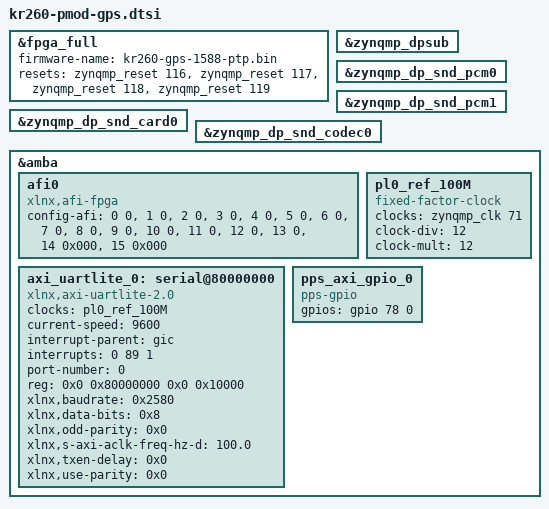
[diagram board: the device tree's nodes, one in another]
// SPDX-License-Identifier: Apache-2.0
/*
 * dts file for Xilinx Kr260 GPS-1588-PTP
 *
 * (C) Copyright 2020 - 2021, Xilinx, Inc.
 * Copyright (C) 2022 - 2024, Advanced Micro Devices, Inc
 *
 */


/dts-v1/;
/plugin/;
&fpga_full {
	#address-cells = <2>;
	#size-cells = <2>;
	firmware-name = "kr260-gps-1588-ptp.bin";
	resets = <&zynqmp_reset 116>, <&zynqmp_reset 117>, <&zynqmp_reset 118>, <&zynqmp_reset 119>;
};

&zynqmp_dpsub {
	status = "okay";
};

&zynqmp_dp_snd_pcm0 {
	status = "okay";
};

&zynqmp_dp_snd_pcm1 {
	status = "okay";
};

&zynqmp_dp_snd_card0 {
	status = "okay";
};

&zynqmp_dp_snd_codec0 {
	status = "okay";
};


&amba {
	#address-cells = <2>;
	#size-cells = <2>;

	afi0: afi0 {
		compatible = "xlnx,afi-fpga";
		config-afi = <0 0>, <1 0>, <2 0>, <3 0>, <4 0>, <5 0>, <6 0>, <7 0>, <8 0>, <9 0>, <10 0>, <11 0>, <12 0>, <13 0>, <14 0x000>, <15 0x000>;
	};

	pl0_ref_100M: pl0_ref_100M {
		#clock-cells = <0x0>;
		compatible = "fixed-factor-clock";
		clocks = <&zynqmp_clk 71>;
		clock-div = <12>;
		clock-mult = <12>;
	};

	axi_uartlite_0: serial@80000000 {
		clock-names = "s_axi_aclk";
		clocks = <&pl0_ref_100M>;
		compatible = "xlnx,axi-uartlite-2.0", "xlnx,xps-uartlite-1.00.a";
		current-speed = <9600>;
		device_type = "serial";
		interrupt-names = "interrupt";
		interrupt-parent = <&gic>;
		interrupts = <0 89 1>;
		port-number = <0>;
		reg = <0x0 0x80000000 0x0 0x10000>;
		xlnx,baudrate = <0x2580>;
		xlnx,data-bits = <0x8>;
		xlnx,odd-parity = <0x0>;
		xlnx,s-axi-aclk-freq-hz-d = "100.0";
		xlnx,txen-delay = <0x0>;
		xlnx,use-parity = <0x0>;
	};

	pps_axi_gpio_0 {
		pinctrl-names = "default";
		gpios = <&gpio 78 0 0 >;
		compatible = "pps-gpio";
	};
};
